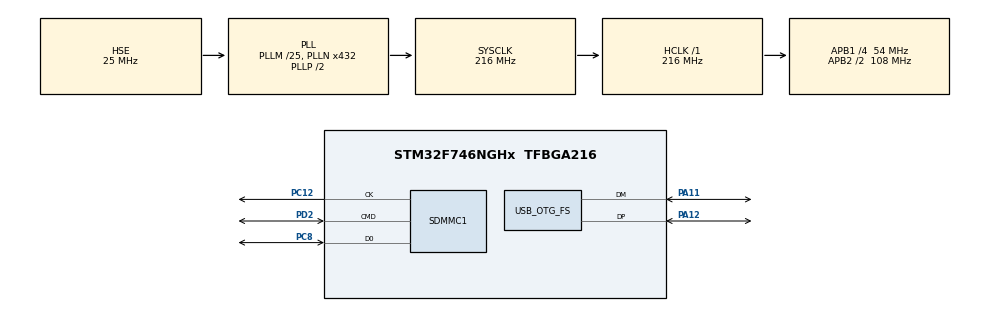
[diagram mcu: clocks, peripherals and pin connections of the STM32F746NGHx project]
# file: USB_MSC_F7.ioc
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CORTEX_M7.default_mode_Activation=1
Dma.Request0=SDMMC1_RX
Dma.Request1=SDMMC1_TX
Dma.SDMMC1_RX.0.Direction=DMA_PERIPH_TO_MEMORY
Dma.SDMMC1_RX.0.FIFOMode=DMA_FIFOMODE_ENABLE
Dma.SDMMC1_RX.0.FIFOThreshold=DMA_FIFO_THRESHOLD_FULL
Dma.SDMMC1_RX.0.Instance=DMA2_Stream3
Dma.SDMMC1_RX.0.MemBurst=DMA_MBURST_INC4
Dma.SDMMC1_RX.0.MemDataAlignment=DMA_MDATAALIGN_WORD
Dma.SDMMC1_RX.0.MemInc=DMA_MINC_ENABLE
Dma.SDMMC1_RX.0.Mode=DMA_PFCTRL
Dma.SDMMC1_RX.0.PeriphBurst=DMA_PBURST_INC4
Dma.SDMMC1_RX.0.PeriphDataAlignment=DMA_PDATAALIGN_WORD
Dma.SDMMC1_RX.0.PeriphInc=DMA_PINC_DISABLE
Dma.SDMMC1_RX.0.Priority=DMA_PRIORITY_LOW
Dma.SDMMC1_TX.1.Direction=DMA_MEMORY_TO_PERIPH
Dma.SDMMC1_TX.1.FIFOMode=DMA_FIFOMODE_ENABLE
Dma.SDMMC1_TX.1.FIFOThreshold=DMA_FIFO_THRESHOLD_FULL
Dma.SDMMC1_TX.1.Instance=DMA2_Stream6
Dma.SDMMC1_TX.1.MemBurst=DMA_MBURST_INC4
Dma.SDMMC1_TX.1.MemDataAlignment=DMA_MDATAALIGN_WORD
Dma.SDMMC1_TX.1.MemInc=DMA_MINC_ENABLE
Dma.SDMMC1_TX.1.Mode=DMA_PFCTRL
Dma.SDMMC1_TX.1.PeriphBurst=DMA_PBURST_INC4
Dma.SDMMC1_TX.1.PeriphDataAlignment=DMA_PDATAALIGN_WORD
Dma.SDMMC1_TX.1.PeriphInc=DMA_PINC_DISABLE
Dma.SDMMC1_TX.1.Priority=DMA_PRIORITY_LOW
FATFS.USE_DMA_CODE_SD=1
Mcu.Family=STM32F7
Mcu.Name=STM32F746NGHx
Mcu.Package=TFBGA216
NVIC.DMA2_Stream3_IRQn=true\:0\:0\:false\:false\:true\:false\:true\:true
NVIC.DMA2_Stream6_IRQn=true\:0\:0\:false\:false\:true\:false\:true\:true
NVIC.OTG_FS_IRQn=true\:0\:0\:false\:false\:true\:false\:true\:true
NVIC.PriorityGroup=NVIC_PRIORITYGROUP_4
PA11.Mode=Device_Only
PA11.Signal=USB_OTG_FS_DM
PA12.Mode=Device_Only
PA12.Signal=USB_OTG_FS_DP
PA13.Mode=Serial_Wire
PA13.Signal=SYS_JTMS-SWDIO
PA14.Mode=Serial_Wire
PA14.Signal=SYS_JTCK-SWCLK
PC12.Mode=SD_1_bit
PC12.Signal=SDMMC1_CK
PC8.Mode=SD_1_bit
PC8.Signal=SDMMC1_D0
PD2.Mode=SD_1_bit
PD2.Signal=SDMMC1_CMD
PH0/OSC_IN.Mode=HSE-External-Clock-Source
PH0/OSC_IN.Signal=RCC_OSC_IN
PH1/OSC_OUT.Mode=HSE-External-Clock-Source
PH1/OSC_OUT.Signal=RCC_OSC_OUT
ProjectManager.HeapSize=0x200
ProjectManager.StackSize=0x400
ProjectManager.TargetToolchain=STM32CubeIDE
RCC.AHBFreq_Value=216000000
RCC.APB1CLKDivider=RCC_HCLK_DIV4
RCC.APB1Freq_Value=54000000
RCC.APB1TimFreq_Value=108000000
RCC.APB2CLKDivider=RCC_HCLK_DIV2
RCC.APB2Freq_Value=108000000
RCC.APB2TimFreq_Value=216000000
RCC.CortexFreq_Value=216000000
RCC.HCLKFreq_Value=216000000
RCC.HSE_VALUE=25000000
RCC.HSI_VALUE=16000000
RCC.LSE_VALUE=32768
RCC.PLLM=25
RCC.PLLN=432
RCC.PLLQ=9
RCC.SDMMCClockSelection=RCC_SDMMC1CLKSOURCE_CLK48
RCC.SYSCLKFreq_VALUE=216000000
RCC.SYSCLKSource=RCC_SYSCLKSOURCE_PLLCLK
RCC.USBFreq_Value=48000000
RCC.VCOOutputFreq_Value=432000000
USB_DEVICE.CLASS_NAME_FS=MSC
USB_DEVICE.VirtualMode-MSC_FS=Msc
USB_DEVICE.VirtualModeFS=Msc_FS
USB_OTG_FS.VirtualMode=Device_Only
VP_FATFS_VS_SDIO.Mode=SDIO
VP_USB_DEVICE_VS_USB_DEVICE_MSC_FS.Mode=MSC_FS
board=custom

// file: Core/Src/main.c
/* USER CODE BEGIN Header */
/**
 ******************************************************************************
 * @file           : main.c
 * @brief          : Main program body
 ******************************************************************************
 * @attention
 *
 * Copyright (c) 2024 STMicroelectronics.
 * All rights reserved.
 *
 * This software is licensed under terms that can be found in the LICENSE file
 * in the root directory of this software component.
 * If no LICENSE file comes with this software, it is provided AS-IS.
 *
 ******************************************************************************
 */
/* USER CODE END Header */
#include "main.h"
#include "fatfs.h"
#include "usb_device.h"

SD_HandleTypeDef hsd1;
DMA_HandleTypeDef hdma_sdmmc1_rx;
DMA_HandleTypeDef hdma_sdmmc1_tx;

/* USER CODE BEGIN PV */
FRESULT fr = FR_NOT_READY;
FATFS   SDFatFs_main; /* File system object for SD card logical drive */
/* USER CODE END PV */

void SystemClock_Config(void);
static void MPU_Config(void);
static void MX_GPIO_Init(void);
static void MX_DMA_Init(void);
static void MX_SDMMC1_SD_Init(void);

int main(void)
{

  /* MPU Configuration--------------------------------------------------------*/
  MPU_Config();

  /* MCU Configuration--------------------------------------------------------*/

  /* Reset of all peripherals, Initializes the Flash interface and the Systick. */
  HAL_Init();

  /* Configure the system clock */
  SystemClock_Config();

  /* Initialize all configured peripherals */
  MX_GPIO_Init();
  MX_DMA_Init();
  MX_SDMMC1_SD_Init();
  MX_FATFS_Init();
  MX_USB_DEVICE_Init();
  /* USER CODE BEGIN 2 */
  if (HAL_SD_Init(&hsd1) != HAL_OK)
  {
    Error_Handler();
  }

  if (HAL_SD_ConfigWideBusOperation(&hsd1, SDMMC_BUS_WIDE_4B) != HAL_OK)
  {
    Error_Handler();
  }

  fr = f_mount(&SDFatFs_main, "", 1);
  MX_USB_DEVICE_Init();
  /* USER CODE END 2 */

  /* Infinite loop */
  while (1)
  {

  }
}

void SystemClock_Config(void)
{
  RCC_OscInitTypeDef RCC_OscInitStruct = {0};
  RCC_ClkInitTypeDef RCC_ClkInitStruct = {0};

  /** Configure the main internal regulator output voltage
  */
  __HAL_RCC_PWR_CLK_ENABLE();
  __HAL_PWR_VOLTAGESCALING_CONFIG(PWR_REGULATOR_VOLTAGE_SCALE1);

  /** Initializes the RCC Oscillators according to the specified parameters
  * in the RCC_OscInitTypeDef structure.
  */
  RCC_OscInitStruct.OscillatorType = RCC_OSCILLATORTYPE_HSE;
  RCC_OscInitStruct.HSEState = RCC_HSE_BYPASS;
  RCC_OscInitStruct.PLL.PLLState = RCC_PLL_ON;
  RCC_OscInitStruct.PLL.PLLSource = RCC_PLLSOURCE_HSE;
  RCC_OscInitStruct.PLL.PLLM = 25;
  RCC_OscInitStruct.PLL.PLLN = 432;
  RCC_OscInitStruct.PLL.PLLP = RCC_PLLP_DIV2;
  RCC_OscInitStruct.PLL.PLLQ = 9;
  if (HAL_RCC_OscConfig(&RCC_OscInitStruct) != HAL_OK)
  {
    Error_Handler();
  }

  /** Activate the Over-Drive mode
  */
  if (HAL_PWREx_EnableOverDrive() != HAL_OK)
  {
    Error_Handler();
  }

  /** Initializes the CPU, AHB and APB buses clocks
  */
  RCC_ClkInitStruct.ClockType = RCC_CLOCKTYPE_HCLK|RCC_CLOCKTYPE_SYSCLK
                              |RCC_CLOCKTYPE_PCLK1|RCC_CLOCKTYPE_PCLK2;
  RCC_ClkInitStruct.SYSCLKSource = RCC_SYSCLKSOURCE_PLLCLK;
  RCC_ClkInitStruct.AHBCLKDivider = RCC_SYSCLK_DIV1;
  RCC_ClkInitStruct.APB1CLKDivider = RCC_HCLK_DIV4;
  RCC_ClkInitStruct.APB2CLKDivider = RCC_HCLK_DIV2;

  if (HAL_RCC_ClockConfig(&RCC_ClkInitStruct, FLASH_LATENCY_7) != HAL_OK)
  {
    Error_Handler();
  }
}

static void MX_SDMMC1_SD_Init(void)
{

  hsd1.Instance = SDMMC1;
  hsd1.Init.ClockEdge = SDMMC_CLOCK_EDGE_RISING;
  hsd1.Init.ClockBypass = SDMMC_CLOCK_BYPASS_DISABLE;
  hsd1.Init.ClockPowerSave = SDMMC_CLOCK_POWER_SAVE_DISABLE;
  hsd1.Init.BusWide = SDMMC_BUS_WIDE_1B;
  hsd1.Init.HardwareFlowControl = SDMMC_HARDWARE_FLOW_CONTROL_DISABLE;
  hsd1.Init.ClockDiv = 0;

}

static void MX_DMA_Init(void)
{

  /* DMA controller clock enable */
  __HAL_RCC_DMA2_CLK_ENABLE();

  /* DMA interrupt init */
  /* DMA2_Stream3_IRQn interrupt configuration */
  HAL_NVIC_SetPriority(DMA2_Stream3_IRQn, 0, 0);
  HAL_NVIC_EnableIRQ(DMA2_Stream3_IRQn);
  /* DMA2_Stream6_IRQn interrupt configuration */
  HAL_NVIC_SetPriority(DMA2_Stream6_IRQn, 0, 0);
  HAL_NVIC_EnableIRQ(DMA2_Stream6_IRQn);

}

static void MX_GPIO_Init(void)
{

  /* GPIO Ports Clock Enable */
  __HAL_RCC_GPIOC_CLK_ENABLE();
  __HAL_RCC_GPIOA_CLK_ENABLE();
  __HAL_RCC_GPIOD_CLK_ENABLE();
  __HAL_RCC_GPIOH_CLK_ENABLE();

}

 /* MPU Configuration */

void MPU_Config(void)
{
  MPU_Region_InitTypeDef MPU_InitStruct = {0};

  /* Disables the MPU */
  HAL_MPU_Disable();

  /** Initializes and configures the Region and the memory to be protected
  */
  MPU_InitStruct.Enable = MPU_REGION_ENABLE;
  MPU_InitStruct.Number = MPU_REGION_NUMBER0;
  MPU_InitStruct.BaseAddress = 0x0;
  MPU_InitStruct.Size = MPU_REGION_SIZE_4GB;
  MPU_InitStruct.SubRegionDisable = 0x87;
  MPU_InitStruct.TypeExtField = MPU_TEX_LEVEL0;
  MPU_InitStruct.AccessPermission = MPU_REGION_NO_ACCESS;
  MPU_InitStruct.DisableExec = MPU_INSTRUCTION_ACCESS_DISABLE;
  MPU_InitStruct.IsShareable = MPU_ACCESS_SHAREABLE;
  MPU_InitStruct.IsCacheable = MPU_ACCESS_NOT_CACHEABLE;
  MPU_InitStruct.IsBufferable = MPU_ACCESS_NOT_BUFFERABLE;

  HAL_MPU_ConfigRegion(&MPU_InitStruct);
  /* Enables the MPU */
  HAL_MPU_Enable(MPU_PRIVILEGED_DEFAULT);

}

void Error_Handler(void)
{
  __disable_irq();
  while (1)
  {
  }
}

#ifdef  USE_FULL_ASSERT
/**
  * @brief  Reports the name of the source file and the source line number
  *         where the assert_param error has occurred.
  * @param  file: pointer to the source file name
  * @param  line: assert_param error line source number
  * @retval None
  */
void assert_failed(uint8_t *file, uint32_t line)
{
  /* USER CODE BEGIN 6 */
  /* User can add his own implementation to report the file name and line
     number, ex: printf("Wrong parameters value: file %s on line %d\r\n", file,
     line) */
  /* USER CODE END 6 */
}
#endif /* USE_FULL_ASSERT */
